# nrf9120_modem register map
Vendor: Nordic Semiconductor; Series: nrf91; File version: 1
CPU: CM4 r0p1, little endian, MPU, FPU, 3 interrupt priority bits
Registers are 32-bit, read-write, reset 0x0 unless marked. A register's access mark holds for its fields unless they carry their own. Offsets are from the block's base; [hi:lo] are bit positions; {n}, {i} and the like mark numbered series; 'fields as' and 'values as' point back to an identical list.

## LFCLKCALIBMEAS_NS — LfClk Calibration Measurement
Base 0x4003B000
0x00 TASKS_START wo — Start Measuring
  [0] TASKS_START
    1=Trigger task
0x04 TASKS_STOP wo — Switch LfClkCalibMeas to STOPPED state. Brings LfClkCalibMeas from SHUTDOWN state to a configurable state before a measurement is launched.
  [0] TASKS_STOP
    1=Trigger task
0x08 TASKS_SHUTDOWN wo — Shut down LfClkCalibMeas
  [0] TASKS_SHUTDOWN
    1=Trigger task
0x100 EVENTS_COMPLETE — Measurement completed.
  [0] EVENTS_COMPLETE
    0=NotGenerated (Event not generated); 1=Generated (Event generated)
0x300 INTEN — Enable or disable interrupt
  [0] COMPLETE — Enable or disable interrupt for event COMPLETE
    0=Disabled; 1=Enabled
0x304 INTENSET — Enable interrupt
  [0] COMPLETE — Write '1' to enable interrupt for event COMPLETE
    on read: 0=Disabled (Read: Disabled); 1=Enabled (Read: Enabled) | on write: 1=Set (Enable)
0x308 INTENCLR — Disable interrupt
  [0] COMPLETE — Write '1' to disable interrupt for event COMPLETE
    on read: 0=Disabled (Read: Disabled); 1=Enabled (Read: Enabled) | on write: 1=Clear (Disable)
0x30C INTPEND ro — Pending interrupts
  [0] COMPLETE — Read pending status of interrupt for event COMPLETE
    on read: 0=NotPending (Read: Not pending); 1=Pending (Read: Pending)
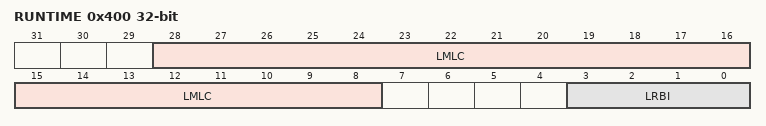
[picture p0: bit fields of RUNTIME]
0x400 RUNTIME ro — Runtime status of the measurement.
  [28:8] LMLC — lastMeasuredLfCycle
  [3:0] LRBI — LastRingBufferIndex
0x404 LCMEAS0 ro — Results of the measurement.
  [31:0] LCMEAS — LfClk Measurement result for the series0.
0x408 LCMEAS1 ro — Results of the measurement.
  [31:0] LCMEAS — LfClk Measurement result for the series1.
{0x404+4i} LCMEAS{i} ro (i=2..4) — Results of the measurement.
  [31:0] LCMEAS — LfClk Measurement results for the series{i}.
0x418 LCMEAS5 ro — Results of the measurement.
  [31:0] LCMEAS — LfClk Measurement results for the series5. Only available, if HW parameter NUM_MEASUREMENTS set to larger than five.
0x41C LCMEAS6 ro — Results of the measurement.
  [31:0] LCMEAS — LfClk Measurement results for the series6. Only available, if HW parameter NUM_MEASUREMENTS set to larger than six.
0x420 LCMEAS7 ro — Results of the measurement.
  [31:0] LCMEAS — LfClk Measurement results for the series7. Only available, if HW parameter NUM_MEASUREMENTS set to larger than seven.
0x424 LCMEAS8 ro — Results of the measurement.
  [31:0] LCMEAS — LfClk Measurement results for the series8. Only available, if HW parameter NUM_MEASUREMENTS set to larger than eight.
0x428 LCMEAS9 ro — Results of the measurement.
  [31:0] LCMEAS — LfClk Measurement results for the series9. Only available, if HW parameter NUM_MEASUREMENTS set to larger than nine.
0x42C STATE ro — Current running state of the IP.
  [1:0] STATE
    0=SHUTDOWN (In SHUTDOWN.); 1=STOPPED (In STOPPED.); 2=RUNNING (In RUNNING.); 3=NA
0x500 MEASLEN — Length of the measurement.
  [20:0] MEASLEN

## CTRL_AP_PERI_S — Control access port
Base 0x4003D000
0x400 CTRLDAP2COREDATA ro — Data sent from the Debugger to the Core
  [31:0] DATA — General Data
0x404 CTRLDAP2CORESTATUS ro — Status to indicate if Data sent from the Debugger to the Core has been read
  [0] STATUS — Status of data in CTRLDAP2COREDATA register
    0=No data pending in CTRLDAP2COREDATA; 1=Data pending in CTRLDAP2COREDATA
0x480 CORE2CTRLDAPDATA — Data sent from the Core to the Debugger
  [31:0] DATA — General Data
0x484 CORE2CTRLDAPSTATUS ro — Status to indicate if Data sent from the Core to the Debugger status has been read
  [0] STATUS — Status of data in CORE2CTRLDAPDATA register
    values as CTRLDAP2CORESTATUS.STATUS
0x500 CPURETURNFIELD_LOCK wo — Lock Mail Box erase all mechanism
  [0] LOCK — Enable or disable the erase all mechanism for return field case. A write once register.
    0=Enabled (Eraseall for return field can be issued); 1=Disabled (Eraseall for return field is locked)
0x504 CPURETURNFIELD wo — Mail box erase all control register. A write once register.
  [31:0] STATUS — Random value to generate a eraseall for return field case.
